AUTOSAR XML (schema 4-2-2)
package /ASW_WDG
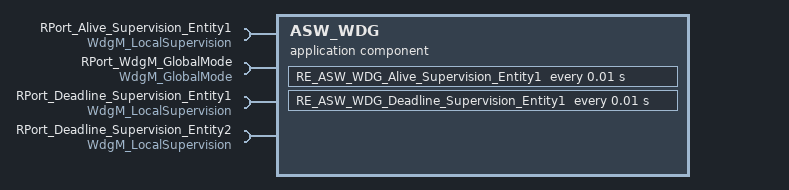
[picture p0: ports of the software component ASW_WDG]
  application sw component type ASW_WDG
    4 x require port:
      RPort_Alive_Supervision_Entity1: required-interface=WdgM_LocalSupervision
      RPort_WdgM_GlobalMode: required-interface=WdgM_GlobalMode
      RPort_Deadline_Supervision_Entity1: required-interface=WdgM_LocalSupervision
      RPort_Deadline_Supervision_Entity2: required-interface=WdgM_LocalSupervision
    behavior IB_ASW_WDG: data-type-mapping=WdgM_Type_Map
      timing event TimingEvent_Alive_Supervision_Entity1: start-on-event=RE_ASW_WDG_Alive_Supervision_Entity1, period=0.01
      timing event TimingEvent_Deadline_Supervision_Entity1: start-on-event=RE_ASW_WDG_Deadline_Supervision_Entity1, period=0.01
      runnable RE_ASW_WDG_Alive_Supervision_Entity1: symbol=RE_ASW_WDG_Alive_Supervision_Entity1_func
        sync call SynchronousServerCallPoint_0: operation=RPort_Alive_Supervision_Entity1.CheckpointReached
      runnable RE_ASW_WDG_Deadline_Supervision_Entity1: symbol=RE_ASW_WDG_Deadline_Supervision_Entity1_func
        sync call SynchronousServerCallPoint_0: operation=RPort_Deadline_Supervision_Entity2.CheckpointReached
        sync call SynchronousServerCallPoint_1: operation=RPort_Deadline_Supervision_Entity1.CheckpointReached
